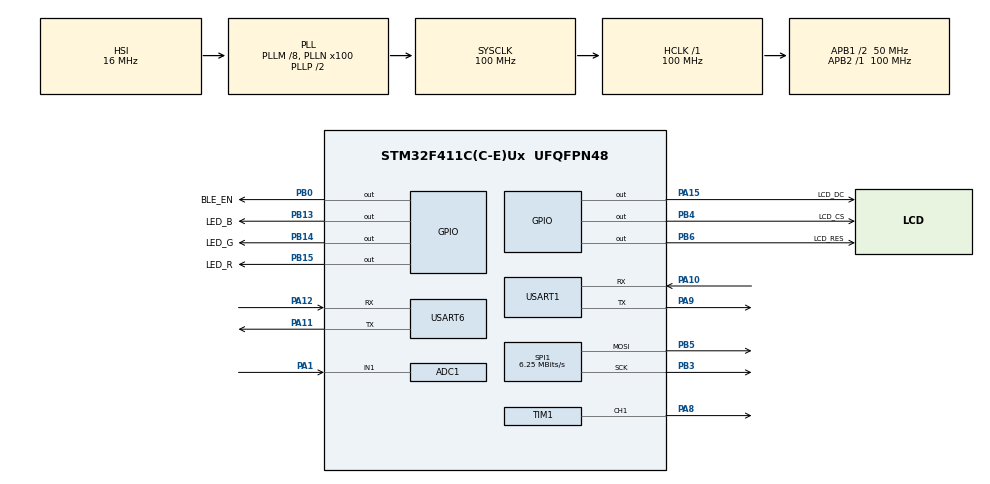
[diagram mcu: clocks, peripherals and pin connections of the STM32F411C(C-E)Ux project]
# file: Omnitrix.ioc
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ADC1.Channel-0\#ChannelRegularConversion=ADC_CHANNEL_1
ADC1.NbrOfConversion=1
ADC1.NbrOfConversionFlag=1
ADC1.Rank-0\#ChannelRegularConversion=1
ADC1.SamplingTime-0\#ChannelRegularConversion=ADC_SAMPLETIME_3CYCLES
ADC1.master=1
Dma.ADC1.0.Direction=DMA_PERIPH_TO_MEMORY
Dma.ADC1.0.FIFOMode=DMA_FIFOMODE_DISABLE
Dma.ADC1.0.Instance=DMA2_Stream0
Dma.ADC1.0.MemDataAlignment=DMA_MDATAALIGN_HALFWORD
Dma.ADC1.0.MemInc=DMA_MINC_ENABLE
Dma.ADC1.0.Mode=DMA_CIRCULAR
Dma.ADC1.0.PeriphDataAlignment=DMA_PDATAALIGN_HALFWORD
Dma.ADC1.0.PeriphInc=DMA_PINC_DISABLE
Dma.ADC1.0.Priority=DMA_PRIORITY_LOW
Dma.Request0=ADC1
Dma.Request1=SPI1_TX
Dma.Request2=USART6_RX
Dma.Request3=USART6_TX
Dma.SPI1_TX.1.Direction=DMA_MEMORY_TO_PERIPH
Dma.SPI1_TX.1.FIFOMode=DMA_FIFOMODE_DISABLE
Dma.SPI1_TX.1.Instance=DMA2_Stream2
Dma.SPI1_TX.1.MemDataAlignment=DMA_MDATAALIGN_BYTE
Dma.SPI1_TX.1.MemInc=DMA_MINC_ENABLE
Dma.SPI1_TX.1.Mode=DMA_NORMAL
Dma.SPI1_TX.1.PeriphDataAlignment=DMA_PDATAALIGN_BYTE
Dma.SPI1_TX.1.PeriphInc=DMA_PINC_DISABLE
Dma.SPI1_TX.1.Priority=DMA_PRIORITY_LOW
Dma.USART6_RX.2.Direction=DMA_PERIPH_TO_MEMORY
Dma.USART6_RX.2.FIFOMode=DMA_FIFOMODE_DISABLE
Dma.USART6_RX.2.Instance=DMA2_Stream1
Dma.USART6_RX.2.MemDataAlignment=DMA_MDATAALIGN_BYTE
Dma.USART6_RX.2.MemInc=DMA_MINC_ENABLE
Dma.USART6_RX.2.Mode=DMA_NORMAL
Dma.USART6_RX.2.PeriphDataAlignment=DMA_PDATAALIGN_BYTE
Dma.USART6_RX.2.PeriphInc=DMA_PINC_DISABLE
Dma.USART6_RX.2.Priority=DMA_PRIORITY_VERY_HIGH
Dma.USART6_TX.3.Direction=DMA_MEMORY_TO_PERIPH
Dma.USART6_TX.3.FIFOMode=DMA_FIFOMODE_DISABLE
Dma.USART6_TX.3.Instance=DMA2_Stream6
Dma.USART6_TX.3.MemDataAlignment=DMA_MDATAALIGN_BYTE
Dma.USART6_TX.3.MemInc=DMA_MINC_ENABLE
Dma.USART6_TX.3.Mode=DMA_NORMAL
Dma.USART6_TX.3.PeriphDataAlignment=DMA_PDATAALIGN_BYTE
Dma.USART6_TX.3.PeriphInc=DMA_PINC_DISABLE
Dma.USART6_TX.3.Priority=DMA_PRIORITY_MEDIUM
FREERTOS.Tasks01=defaultTask,24,128,StartDefaultTask,Default,NULL,Dynamic,NULL,NULL;initTask,8,256,initFunction,As weak,NULL,Dynamic,NULL,NULL
Mcu.Family=STM32F4
Mcu.Name=STM32F411C(C-E)Ux
Mcu.Package=UFQFPN48
NVIC.DMA2_Stream0_IRQn=true\:5\:0\:false\:false\:true\:true\:false\:true\:true
NVIC.DMA2_Stream1_IRQn=true\:5\:0\:false\:false\:true\:true\:false\:true\:true
NVIC.DMA2_Stream2_IRQn=true\:5\:0\:false\:false\:true\:true\:false\:true\:true
NVIC.DMA2_Stream6_IRQn=true\:5\:0\:false\:false\:true\:true\:false\:true\:true
NVIC.PriorityGroup=NVIC_PRIORITYGROUP_4
NVIC.RTC_WKUP_IRQn=true\:5\:0\:false\:false\:true\:true\:true\:true\:true
NVIC.TIM3_IRQn=true\:15\:0\:false\:false\:true\:false\:false\:true\:true
NVIC.TimeBase=TIM3_IRQn
NVIC.TimeBaseIP=TIM3
NVIC.USART6_IRQn=true\:5\:0\:false\:false\:true\:true\:true\:true\:true
PA1.Signal=ADCx_IN1
PA10.Mode=Asynchronous
PA10.Signal=USART1_RX
PA11.Mode=Asynchronous
PA11.Signal=USART6_TX
PA12.Mode=Asynchronous
PA12.Signal=USART6_RX
PA13.Mode=Serial_Wire
PA13.Signal=SYS_JTMS-SWDIO
PA14.Mode=Serial_Wire
PA14.Signal=SYS_JTCK-SWCLK
PA15.GPIO_Label=LCD_DC
PA15.Signal=GPIO_Output
PA8.Signal=S_TIM1_CH1
PA9.Mode=Asynchronous
PA9.Signal=USART1_TX
PB0.GPIO_Label=BLE_EN
PB0.Signal=GPIO_Output
PB13.GPIO_Label=LED_B
PB13.GPIO_Speed=GPIO_SPEED_FREQ_HIGH
PB13.PinState=GPIO_PIN_SET
PB13.Signal=GPIO_Output
PB14.GPIO_Label=LED_G
PB14.GPIO_Speed=GPIO_SPEED_FREQ_HIGH
PB14.PinState=GPIO_PIN_SET
PB14.Signal=GPIO_Output
PB15.GPIO_Label=LED_R
PB15.GPIO_Speed=GPIO_SPEED_FREQ_HIGH
PB15.PinState=GPIO_PIN_SET
PB15.Signal=GPIO_Output
PB3.Mode=TX_Only_Simplex_Unidirect_Master
PB3.Signal=SPI1_SCK
PB4.GPIO_Label=LCD_CS
PB4.Signal=GPIO_Output
PB5.Mode=TX_Only_Simplex_Unidirect_Master
PB5.Signal=SPI1_MOSI
PB6.GPIO_Label=LCD_RES
PB6.Signal=GPIO_Output
PC14-OSC32_IN.Mode=LSE-External-Oscillator
PC14-OSC32_IN.Signal=RCC_OSC32_IN
PC15-OSC32_OUT.Mode=LSE-External-Oscillator
PC15-OSC32_OUT.Signal=RCC_OSC32_OUT
ProjectManager.HeapSize=0x200
ProjectManager.StackSize=0x400
ProjectManager.TargetToolchain=CMake
RCC.48MHZClocksFreq_Value=50000000
RCC.AHBFreq_Value=100000000
RCC.APB1CLKDivider=RCC_HCLK_DIV2
RCC.APB1Freq_Value=50000000
RCC.APB1TimFreq_Value=100000000
RCC.APB2Freq_Value=100000000
RCC.APB2TimFreq_Value=100000000
RCC.CortexFreq_Value=100000000
RCC.HCLKFreq_Value=100000000
RCC.HSE_VALUE=25000000
RCC.HSI_VALUE=16000000
RCC.PLLM=8
RCC.PLLN=100
RCC.SYSCLKFreq_VALUE=100000000
RCC.SYSCLKSource=RCC_SYSCLKSOURCE_PLLCLK
RCC.VCOOutputFreq_Value=200000000
RTC.Date=21
RTC.Hours=11
RTC.Minutes=59
RTC.Month=RTC_MONTH_MAY
RTC.Seconds=55
RTC.WakeUpCounter=2000
RTC.WeekDay=RTC_WEEKDAY_SUNDAY
RTC.Year=23
SH.ADCx_IN1.0=ADC1_IN1,IN1
SH.S_TIM1_CH1.0=TIM1_CH1,PWM Generation1 CH1
SPI1.BaudRatePrescaler=SPI_BAUDRATEPRESCALER_16
SPI1.CLKPhase=SPI_PHASE_1EDGE
SPI1.CLKPolarity=SPI_POLARITY_LOW
SPI1.CalculateBaudRate=6.25 MBits/s
SPI1.Direction=SPI_DIRECTION_2LINES
SPI1.Mode=SPI_MODE_MASTER
SPI1.VirtualType=VM_MASTER
TIM1.Channel-PWM\ Generation1\ CH1=TIM_CHANNEL_1
TIM1.Period=300
TIM1.Prescaler=100-1
USART1.VirtualMode=VM_ASYNC
USART6.VirtualMode=VM_ASYNC
VP_FREERTOS_VS_CMSIS_V2.Mode=CMSIS_V2
VP_RTC_VS_RTC_Activate.Mode=RTC_Enabled
VP_RTC_VS_RTC_Calendar.Mode=RTC_Calendar
VP_RTC_VS_RTC_WakeUp_intern.Mode=WakeUp
VP_SYS_VS_tim3.Mode=TIM3
VP_TIM1_VS_ClockSourceINT.Mode=Internal
board=custom

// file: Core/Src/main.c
/* USER CODE BEGIN Header */
/**
 ******************************************************************************
 * @file           : main.c
 * @brief          : Main program body
 ******************************************************************************
 * @attention
 *
 * Copyright (c) 2025 STMicroelectronics.
 * All rights reserved.
 *
 * This software is licensed under terms that can be found in the LICENSE file
 * in the root directory of this software component.
 * If no LICENSE file comes with this software, it is provided AS-IS.
 *
 ******************************************************************************
 */
/* USER CODE END Header */
#include "main.h"
#include "cmsis_os.h"
#include "adc.h"
#include "dma.h"
#include "rtc.h"
#include "spi.h"
#include "tim.h"
#include "usart.h"
#include "gpio.h"

void SystemClock_Config(void);
void MX_FREERTOS_Init(void);

int main(void)
{

  /* MCU Configuration--------------------------------------------------------*/

  /* Reset of all peripherals, Initializes the Flash interface and the Systick. */
  HAL_Init();

  /* Configure the system clock */
  SystemClock_Config();

  /* USER CODE BEGIN SysInit */
  delay_init();
  /* USER CODE END SysInit */

  /* Initialize all configured peripherals */
  MX_GPIO_Init();
  MX_DMA_Init();
  MX_ADC1_Init();
  MX_RTC_Init();
  MX_USART1_UART_Init();
  MX_USART6_UART_Init();
  MX_TIM1_Init();
  MX_SPI1_Init();

  /* Init scheduler */
  osKernelInitialize(); /* Call init function for freertos objects (in cmsis_os2.c) */
  MX_FREERTOS_Init();

  /* Start scheduler */
  osKernelStart();

  /* We should never get here as control is now taken by the scheduler */

  /* Infinite loop */
  while (1)
  {

  }
}

void SystemClock_Config(void)
{
  RCC_OscInitTypeDef RCC_OscInitStruct = {0};
  RCC_ClkInitTypeDef RCC_ClkInitStruct = {0};

  /** Configure the main internal regulator output voltage
   */
  __HAL_RCC_PWR_CLK_ENABLE();
  __HAL_PWR_VOLTAGESCALING_CONFIG(PWR_REGULATOR_VOLTAGE_SCALE1);

  /** Initializes the RCC Oscillators according to the specified parameters
   * in the RCC_OscInitTypeDef structure.
   */
  RCC_OscInitStruct.OscillatorType = RCC_OSCILLATORTYPE_HSI | RCC_OSCILLATORTYPE_LSI;
  RCC_OscInitStruct.HSIState = RCC_HSI_ON;
  RCC_OscInitStruct.HSICalibrationValue = RCC_HSICALIBRATION_DEFAULT;
  RCC_OscInitStruct.LSIState = RCC_LSI_ON;
  RCC_OscInitStruct.PLL.PLLState = RCC_PLL_ON;
  RCC_OscInitStruct.PLL.PLLSource = RCC_PLLSOURCE_HSI;
  RCC_OscInitStruct.PLL.PLLM = 8;
  RCC_OscInitStruct.PLL.PLLN = 100;
  RCC_OscInitStruct.PLL.PLLP = RCC_PLLP_DIV2;
  RCC_OscInitStruct.PLL.PLLQ = 4;
  if (HAL_RCC_OscConfig(&RCC_OscInitStruct) != HAL_OK)
  {
    Error_Handler();
  }

  /** Initializes the CPU, AHB and APB buses clocks
   */
  RCC_ClkInitStruct.ClockType = RCC_CLOCKTYPE_HCLK | RCC_CLOCKTYPE_SYSCLK | RCC_CLOCKTYPE_PCLK1 | RCC_CLOCKTYPE_PCLK2;
  RCC_ClkInitStruct.SYSCLKSource = RCC_SYSCLKSOURCE_PLLCLK;
  RCC_ClkInitStruct.AHBCLKDivider = RCC_SYSCLK_DIV1;
  RCC_ClkInitStruct.APB1CLKDivider = RCC_HCLK_DIV2;
  RCC_ClkInitStruct.APB2CLKDivider = RCC_HCLK_DIV1;

  if (HAL_RCC_ClockConfig(&RCC_ClkInitStruct, FLASH_LATENCY_3) != HAL_OK)
  {
    Error_Handler();
  }
}

void HAL_TIM_PeriodElapsedCallback(TIM_HandleTypeDef *htim)
{
  if (htim->Instance == TIM3)
  {
    HAL_IncTick();
  }
}

void Error_Handler(void)
{
  __disable_irq();
  while (1)
  {
  }
}

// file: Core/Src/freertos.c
/* USER CODE BEGIN Header */
/**
  ******************************************************************************
  * File Name          : freertos.c
  * Description        : Code for freertos applications
  ******************************************************************************
  * @attention
  *
  * Copyright (c) 2025 STMicroelectronics.
  * All rights reserved.
  *
  * This software is licensed under terms that can be found in the LICENSE file
  * in the root directory of this software component.
  * If no LICENSE file comes with this software, it is provided AS-IS.
  *
  ******************************************************************************
  */
/* USER CODE END Header */

#include "FreeRTOS.h"
#include "task.h"
#include "main.h"
#include "cmsis_os.h"

/* Definitions for defaultTask */
osThreadId_t defaultTaskHandle;
const osThreadAttr_t defaultTask_attributes = {
  .name = "defaultTask",
  .stack_size = 128 * 4,
  .priority = (osPriority_t) osPriorityNormal,
};
/* Definitions for initTask */
osThreadId_t initTaskHandle;
const osThreadAttr_t initTask_attributes = {
  .name = "initTask",
  .stack_size = 256 * 4,
  .priority = (osPriority_t) osPriorityLow,
};

void StartDefaultTask(void *argument);
void initFunction(void *argument);

void MX_FREERTOS_Init(void); /* (MISRA C 2004 rule 8.1) */

void MX_FREERTOS_Init(void) {

  /* Create the thread(s) */
  /* creation of defaultTask */
  defaultTaskHandle = osThreadNew(StartDefaultTask, NULL, &defaultTask_attributes);

  /* creation of initTask */
  initTaskHandle = osThreadNew(initFunction, NULL, &initTask_attributes);

}

void StartDefaultTask(void *argument)
{
  for(;;)
  {
    osDelay(1);
  }
}

__weak void initFunction(void *argument)
{
  for(;;)
  {
    osDelay(1);
  }
}
